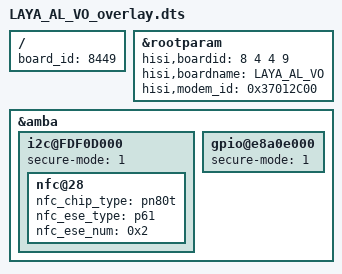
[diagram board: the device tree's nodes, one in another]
/**
 * Copyright (C) 2014 Hisilicon Ltd.
 *
 *  This program is free software; you can redistribute it and/or modify
 *  it under the terms of the GNU General Public License version 2 as
 *  publishhed by the Free Software Foundation.
 */

/dts-v1/;
/plugin/;
/include/ "LAYA_AL_VK_overlay.dtsi"
/include/ "LAYA_AL_VO_pin.dtsi"
/include/ "LAYA_AL_VO_modem_pin.dtsi"

/ {
    board_id = <8449>;
};

	&rootparam{
		hisi,boardid = <8 4 4 9>;
		hisi,boardname = "LAYA_AL_VO";
		hisi,modem_id = <0x37012C00>;
	};

	&amba {
            i2c@FDF0D000 {
		secure-mode = <1>;
                    nfc@28{
                            nfc_chip_type = "pn80t";
                            nfc_ese_type = "p61";
			    nfc_ese_num = <0x2>;
                    };
            };
	    gpio@e8a0e000 {
		secure-mode = <1>;
	    };
    }; 
